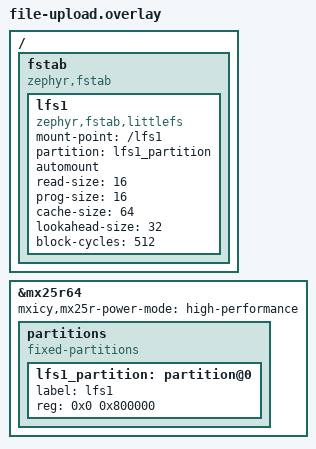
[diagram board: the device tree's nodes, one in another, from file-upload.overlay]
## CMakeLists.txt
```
# SPDX-License-Identifier: Apache-2.0

cmake_minimum_required(VERSION 3.20.0)

find_package(Zephyr REQUIRED HINTS $ENV{ZEPHYR_BASE})
project(mcumgr_repro)

target_sources(app PRIVATE src/main.c)
```

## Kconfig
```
# SPDX-License-Identifier: Apache-2.0

config REPRO_REBOOT_ON_BOOT
	bool "Reboot right after starting"
	select REBOOT
	help
	  Makes the image reboot 300 ms after it starts, like an image that crashes on boot. It
	  never gets to confirm itself, so MCUboot reverts it after its test boot.

source "Kconfig.zephyr"
```

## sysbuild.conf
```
# MCUboot in swap-using-move mode, the nRF Connect SDK default, so an image that fails its test
# boot is reverted.
SB_CONFIG_BOOTLOADER_MCUBOOT=y
SB_CONFIG_MCUBOOT_MODE_SWAP_USING_MOVE=y
```

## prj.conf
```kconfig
# Version of the image, used when it's signed for MCUboot and reported in the image list.
CONFIG_MCUBOOT_IMGTOOL_SIGN_VERSION="1.0.0+0"
CONFIG_BOOTLOADER_MCUBOOT=y

# Bluetooth LE peripheral.
CONFIG_BT=y
CONFIG_BT_PERIPHERAL=y
CONFIG_BT_DEVICE_NAME="SMP repro"

# Large Bluetooth LE packets, as in Zephyr's smp_svr sample.
CONFIG_BT_L2CAP_TX_MTU=498
CONFIG_BT_BUF_ACL_RX_SIZE=502
CONFIG_BT_BUF_ACL_TX_SIZE=502
CONFIG_BT_CTLR_DATA_LENGTH_MAX=251

# MCUmgr over Bluetooth LE, without pairing.
CONFIG_NET_BUF=y
CONFIG_ZCBOR=y
CONFIG_CRC=y
CONFIG_FLASH=y
CONFIG_FLASH_MAP=y
CONFIG_STREAM_FLASH=y
CONFIG_IMG_MANAGER=y
CONFIG_MCUMGR=y
CONFIG_MCUMGR_TRANSPORT_BT=y
CONFIG_MCUMGR_TRANSPORT_BT_CONN_PARAM_CONTROL=y
CONFIG_MCUMGR_TRANSPORT_BT_REASSEMBLY=y
CONFIG_MCUMGR_TRANSPORT_NETBUF_SIZE=2475
CONFIG_MCUMGR_TRANSPORT_WORKQUEUE_STACK_SIZE=4608
CONFIG_MCUMGR_GRP_IMG=y
CONFIG_MCUMGR_GRP_OS=y

# The params command reports the SMP buffer size and count. Zephyr's default is n.
CONFIG_MCUMGR_GRP_OS_MCUMGR_PARAMS=y

# Stack sizes from the smp_svr sample.
CONFIG_SYSTEM_WORKQUEUE_STACK_SIZE=2304
CONFIG_MAIN_STACK_SIZE=2176

# Logs on the UART console (VCOM1 on the nRF54L15 DK).
CONFIG_LOG=y
```

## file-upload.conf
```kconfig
# File uploads to LittleFS at /lfs1, on the DK's external flash (see file-upload.overlay).
CONFIG_FILE_SYSTEM=y
CONFIG_FILE_SYSTEM_LITTLEFS=y
CONFIG_MCUMGR_GRP_FS=y

# 512-byte SMP buffers, so the app uploads about 450 bytes of file data per request. With the
# 2475 bytes of prj.conf, requests are about 2.4 KB and an upload rarely hits the issue.
CONFIG_MCUMGR_TRANSPORT_NETBUF_SIZE=512

CONFIG_BT_DEVICE_NAME="SMP repro files"
```

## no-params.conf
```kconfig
# Without the MCUmgr params command, as with Zephyr's default. The device replies to it with
# rc 8 (MGMT_ERR_ENOTSUP).
CONFIG_MCUMGR_GRP_OS_MCUMGR_PARAMS=n
CONFIG_BT_DEVICE_NAME="SMP repro no params"
```

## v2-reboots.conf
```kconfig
# Image 2.0.0, which fails its test boot. It reboots right after starting, before anything can
# confirm it, so MCUboot reverts to the previous image.
CONFIG_MCUBOOT_IMGTOOL_SIGN_VERSION="2.0.0+0"
CONFIG_REPRO_REBOOT_ON_BOOT=y
```

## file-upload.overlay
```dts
/*
 * LittleFS at /lfs1 on the DK's 8 MB external flash, for the file uploads of file-upload.conf.
 * The internal RRAM has no room for test files.
 */

/ {
	fstab {
		compatible = "zephyr,fstab";

		lfs1: lfs1 {
			compatible = "zephyr,fstab,littlefs";
			mount-point = "/lfs1";
			partition = <&lfs1_partition>;
			automount;
			read-size = <16>;
			prog-size = <16>;
			cache-size = <64>;
			lookahead-size = <32>;
			block-cycles = <512>;
		};
	};
};

&mx25r64 {
	status = "okay";
	/* Faster writes and erases. */
	mxicy,mx25r-power-mode = "high-performance";

	partitions {
		compatible = "fixed-partitions";
		#address-cells = <1>;
		#size-cells = <1>;

		lfs1_partition: partition@0 {
			label = "lfs1";
			reg = <0x0 0x800000>;
		};
	};
};
```

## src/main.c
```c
/*
 * Based on the smp_svr sample of Zephyr:
 * Copyright (c) 2012-2014 Wind River Systems, Inc.
 * Copyright (c) 2020 Prevas A/S
 *
 * SPDX-License-Identifier: Apache-2.0
 */

#include <zephyr/kernel.h>
#include <zephyr/logging/log.h>
#include <zephyr/logging/log_ctrl.h>
#include <zephyr/sys/reboot.h>
#include <zephyr/bluetooth/bluetooth.h>
#include <zephyr/bluetooth/conn.h>
#include <zephyr/bluetooth/hci.h>
#include <zephyr/mgmt/mcumgr/transport/smp_bt.h>

LOG_MODULE_REGISTER(repro, LOG_LEVEL_INF);

static struct k_work advertise_work;

static const struct bt_data ad[] = {
	BT_DATA_BYTES(BT_DATA_FLAGS, (BT_LE_AD_GENERAL | BT_LE_AD_NO_BREDR)),
	BT_DATA_BYTES(BT_DATA_UUID128_ALL, SMP_BT_SVC_UUID_VAL),
};

static const struct bt_data sd[] = {
	BT_DATA(BT_DATA_NAME_COMPLETE, CONFIG_BT_DEVICE_NAME, sizeof(CONFIG_BT_DEVICE_NAME) - 1),
};

static void advertise(struct k_work *work)
{
	int rc = bt_le_adv_start(BT_LE_ADV_CONN_FAST_1, ad, ARRAY_SIZE(ad), sd, ARRAY_SIZE(sd));

	if (rc) {
		LOG_ERR("Advertising failed to start (rc %d)", rc);
		return;
	}
	LOG_INF("Advertising as \"%s\"", CONFIG_BT_DEVICE_NAME);
}

static void connected(struct bt_conn *conn, uint8_t err)
{
	if (err) {
		LOG_ERR("Connection failed, err 0x%02x %s", err, bt_hci_err_to_str(err));
		k_work_submit(&advertise_work);
		return;
	}
	LOG_INF("Connected");
}

static void disconnected(struct bt_conn *conn, uint8_t reason)
{
	LOG_INF("Disconnected, reason 0x%02x %s", reason, bt_hci_err_to_str(reason));
}

static void recycled(void)
{
	/* The connection object is free again, so the device can advertise again. */
	k_work_submit(&advertise_work);
}

BT_CONN_CB_DEFINE(conn_callbacks) = {
	.connected = connected,
	.disconnected = disconnected,
	.recycled = recycled,
};

int main(void)
{
	LOG_INF("Image %s started", CONFIG_MCUBOOT_IMGTOOL_SIGN_VERSION);

	if (IS_ENABLED(CONFIG_REPRO_REBOOT_ON_BOOT)) {
		/* Like an image that crashes on boot, before anything can confirm it. */
		LOG_ERR("Simulating a crash on boot, rebooting");
		/* The log is deferred and would not be printed before the reboot, so flush it now. */
		LOG_PANIC();
		k_sleep(K_MSEC(300));
		sys_reboot(SYS_REBOOT_COLD);
	}

	k_work_init(&advertise_work, advertise);

	int rc = bt_enable(NULL);

	if (rc) {
		LOG_ERR("Bluetooth failed to start (rc %d)", rc);
		return 0;
	}
	k_work_submit(&advertise_work);

	/* MCUmgr requests are handled by the SMP transport, so main() has nothing more to do. */
	return 0;
}
```
